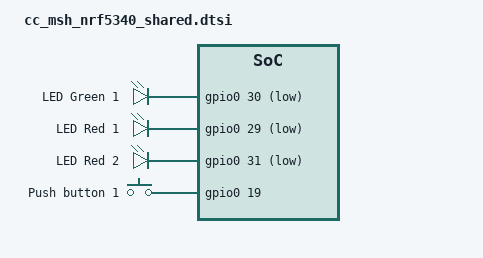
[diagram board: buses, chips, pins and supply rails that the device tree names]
/*
 * Copyright (c) 2024 Classified Cycling BV
 *
 * SPDX-License-Identifier: Apache-2.0
 */

#include <zephyr/dt-bindings/input/input-event-codes.h>

/ {
	leds0 {
		compatible = "gpio-leds";
		led0: led_0 {
			gpios = <&gpio0 30 GPIO_ACTIVE_LOW>;
			label = "LED Green 1";
		};
	};

	leds1 {
		compatible = "gpio-leds";
		led1: led_1 {
			gpios = <&gpio0 29 GPIO_ACTIVE_LOW>;
			label = "LED Red 1";
		};
	};

	leds2 {
		compatible = "gpio-leds";
		led2: led_2 {
			gpios = <&gpio0 31 GPIO_ACTIVE_LOW>;
			label = "LED Red 2";
		};
	};

	buttons {
		compatible = "gpio-keys";
		button0: button_0 {
			gpios = <&gpio0 19 (GPIO_PULL_DOWN | GPIO_ACTIVE_HIGH)>;
			label = "Push button 1";
			zephyr,code = <INPUT_KEY_0>;
		};
	};

	/* These aliases are provided for compatibility with samples */
	aliases {
		led0 = &led0;
		led1 = &led1;
		led2 = &led2;
		sw0 = &button0;
		bootloader-led0 = &led0;
		mcuboot-button0 = &button0;
		mcuboot-led0 = &led0;
	};
};
